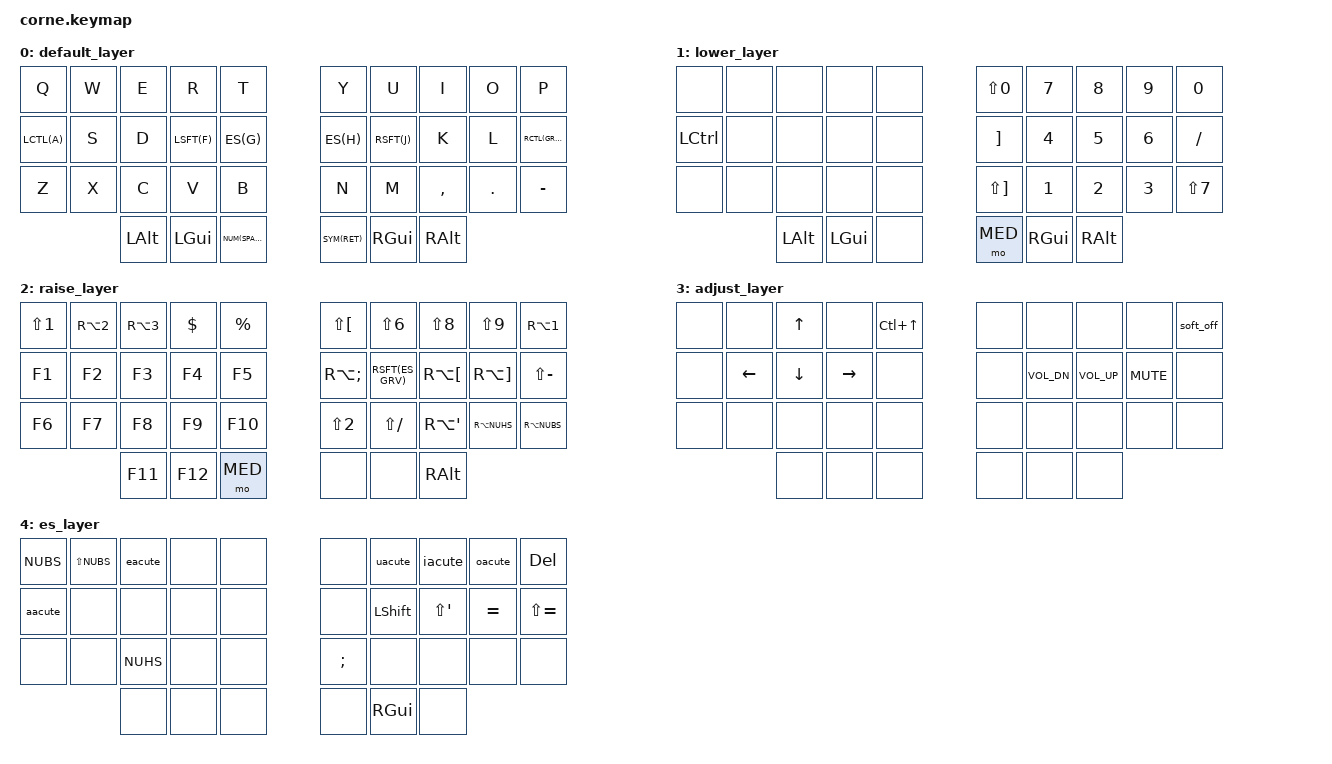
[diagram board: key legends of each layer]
/*
 * Copyright (c) 2020 The ZMK Contributors
 *
 * SPDX-License-Identifier: MIT
 */

// Example configuracion from:
// https://github.com/BerkeleyTrue/zmk-keyboards/blob/master/config/corne.keymap

#include <behaviors.dtsi>
#include <dt-bindings/zmk/keys.h>
#include <dt-bindings/zmk/bt.h>

// Layers
#define DEF     0
#define NUM     1
#define SYM     2
#define MED     3
#define ES      4

#include "keys/36.h"
#include "includes/macros.dtsi"
#include "includes/combos.dtsi"
#include "includes/power.dtsi"


// Short codes
#define ___      &trans      //  transparent
#define _x_      &none

// ES codes
#define ES_LT          &kp GRAVE
#define ES_QUOT        &kp MINUS
#define ES_DQUOT       &kp LS(N2)
#define ES_AT          &kp RA(N2)
#define ES_HASH        &kp RA(N3)
#define ES_CIRC        &kp LS(LBKT)
#define ES_AMP         &kp LS(N6)
#define ES_LPAR        &kp LS(N8)
#define ES_RPAR        &kp LS(N9)
#define ES_GRV         LBKT
#define ES_TILD        &kp RA(SEMI)
#define ES_LBRC        &kp RA(LBKT)
#define ES_RBRC        &kp RA(RBKT)

#define ES_UND         &kp LS(SLASH)
#define ES_LCBR        &kp RA(SQT)
#define ES_RCBR        &kp RA(NUHS)
#define ES_BSLH        &kp RA(NUBS)
#define ES_ORD         &kp NUBS
#define ES_FORD        &kp LS(NUBS)
#define ES_AACUTE      &aacute
#define ES_EACUTE      &eacute
#define ES_IACUTE      &iacute
#define ES_OACUTE      &oacute
#define ES_UACUTE      &uacute
#define ES_NTILD       &kp SEMI
#define ES_DIAE        &kp LS(SQT)
#define ES_IEXL        &kp EQUAL
#define ES_EXCL        &kp LS(N1)
#define ES_IQUE        &kp LS(EQUAL)
#define ES_QUES        &kp LS(MINUS)
#define ES_PIPE        &kp RA(N1)
#define ES_CCED        &kp NUHS

#define ES_EQUAL       &kp LS(N0)
#define ES_PLUS        &kp RBKT
#define ES_ASTRK       &kp LS(RBKT)
#define ES_MINUS       &kp SLASH
#define ES_FSLH        &kp LS(N7)

#define _NUM(k) &lt NUM k
#define _SYM(k) &lt SYM k
#define _ES(k) &lt ES k
#define _LCTL(k) &mt LCTRL k
#define _RCTL(k) &mt RCTRL k
#define _LSFT(k) &mt LSHIFT k
#define _RSFT(k) &mt RSHIFT k

/ {
  chosen {
    zmk,matrix_transform = &five_column_transform;
  };
};

/ {
        keymap {
                compatible = "zmk,keymap";

                default_layer { // layer 0
// -----------------------------------------------------------------
// | Q  |  W  |  E  |  R  |  T  |   |  Y  |  U   |  I  |  O  |  P  |
// | A  |  S  |  D  |  F  |  G  |   |  H  |  J   |  K  |  L  |  <  |
// | Z  |  X  |  C  |  V  |  B  |   |  N  |  M   |  ,  |  .  |  '  |
//            | ALT | GUI | SPC |   | ENT | GUI  | ALT |
                        bindings = <
   &kp Q         &kp W  &kp E     &kp R         &kp T                  &kp Y          &kp U         &kp I      &kp O    &kp P   
   _LCTL(A)      &kp S  &kp D     _LSFT(F)      _ES(G)                 _ES(H)         _RSFT(J)      &kp K      &kp L    _RCTL(GRAVE)
   &kp Z         &kp X  &kp C     &kp V         &kp B                  &kp N          &kp M         &kp COMMA  &kp DOT  ES_QUOT
                        &kp LALT  &kp LGUI      _NUM(SPACE)            _SYM(RET)      &kp RGUI      &kp RALT
                        >;
                };
                
                lower_layer { // layer 1
// -----------------------------------------------------------------
// |     |     |     |     |     |   |  =  |  7  |  8  |  9  |  0  |
// |     |     |     |     |     |   |  +  |  4  |  5  |  6  |  -  |
// |     |     |     |     |     |   |  *  |  1  |  2  |  3  |  /  |
//             | ALT | GUI |     |   |     | GUI | ALT |
                        bindings = <
   _x_       _x_  _x_      _x_      _x_         ES_EQUAL &kp N7   &kp N8   &kp N9  &kp N0
   &kp LCTRL _x_  _x_      _x_      _x_         ES_PLUS  &kp N4   &kp N5   &kp N6  ES_MINUS
   _x_       _x_  _x_      _x_      _x_         ES_ASTRK &kp N1   &kp N2   &kp N3  ES_FSLH
              &kp LALT &kp LGUI _x_             &mo MED  &kp RGUI &kp RALT
                        >;
                };

                raise_layer { // layer 2
// -----------------------------------------------------------------
// |  !  |  @  |  #  |  $  |  %  |   |  ^  |  &  |  (  |  )  |  |  |
// | F1  | F2  | F3  | F4  | F5  |   |  ~  |  `  |  [  |  ]  |  ?  |
// | F6  | F7  | F8  | F9  | F10 |   |  "  |  _  |  {  |  }  |  \  |
//             | F11 | F12 |     |   |     |     | ALT |
                        bindings = <
   ES_EXCL  ES_AT  ES_HASH  &kp DLLR &kp PRCNT       ES_CIRC  ES_AMP        ES_LPAR  ES_RPAR ES_PIPE
   &kp F1   &kp F2 &kp F3   &kp F4   &kp F5          ES_TILD  _RSFT(ES_GRV) ES_LBRC  ES_RBRC ES_QUES
   &kp F6   &kp F7 &kp F8   &kp F9   &kp F10         ES_DQUOT ES_UND        ES_LCBR  ES_RCBR ES_BSLH
                   &kp F11  &kp F12  &mo MED           _x_      _x_         &kp RALT
                         >;
                 };

                adjust_layer { // layer 3
// -----------------------------------------------------------------
// |     |     | Up  |     |MCtrl|   |     |     |     |     | Off |
// |     | Left| Down|Right|     |   |     | Vol-| Vol+| Mute|     |
// |     |     |     |     |     |   |     |     |     |     |     |
//             |     |     |     |   |     |     |     |
                        bindings = <
   _x_      _x_      &kp UP     _x_       &kp LC(UP)  _x_  _x_           _x_           _x_         &soft_off
   _x_      &kp LEFT &kp DOWN   &kp RIGHT _x_         _x_  &kp K_VOL_DN  &kp K_VOL_UP  &kp K_MUTE  _x_
   _x_      _x_      _x_        _x_       _x_         _x_  _x_           _x_           _x_         _x_
                     _x_        _x_       _x_         _x_  _x_           _x_
                        >;
                };

                es_layer { // layer 4 (spanish symbols)
// -----------------------------------------------------------------
// |  º  |  ª  |  é  |     |     |   |     |  ú  |  í  |  ó  | Del |
// |  á  |     |     |     |     |   |     |     |  ¨  |  ¡  |  ¿  |
// |     |     |  ç  |     |     |   |  ñ  |     |     |     |     |
//             |     |     |     |   |     |     |     |
                        bindings = <
   ES_ORD     ES_FORD  ES_EACUTE  _x_  _x_      _x_       ES_UACUTE   ES_IACUTE  ES_OACUTE  &kp DEL
   ES_AACUTE  _x_      _x_        _x_  _x_      _x_       &kp LSHIFT  ES_DIAE    ES_IEXL    ES_IQUE
   _x_        _x_      ES_CCED    _x_  _x_      ES_NTILD  _x_         _x_        _x_        _x_
                       _x_        _x_  _x_      _x_       &kp RGUI    _x_
                        >;
                };
        };
};
